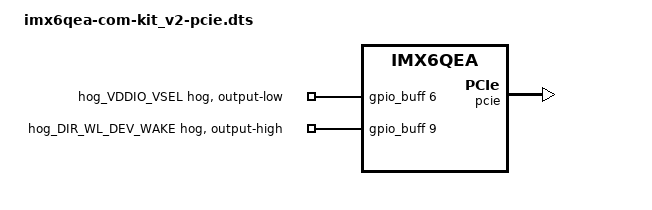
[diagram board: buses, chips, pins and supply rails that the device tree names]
/*
 * Copyright 2012 Freescale Semiconductor, Inc.
 * Copyright 2011 Linaro Ltd.
 *
 * The code contained herein is licensed under the GNU General Public
 * License. You may obtain a copy of the GNU General Public License
 * Version 2 or later at the following locations:
 *
 * http://www.opensource.org/licenses/gpl-license.html
 * http://www.gnu.org/copyleft/gpl.html
 */

/dts-v1/;
 
#include "imx6qea-com-kit_v2.dts"


&gpio_buff {
	hog_VDDIO_VSEL {
		gpio-hog;
		gpios = <6 0>;
		/delete-property/ output-high;
		output-low; /* LOW = 1.8V, HIGH = 3.3V */
	};
	hog_DIR_WL_DEV_WAKE {
		gpio-hog;
		gpios = <9 0>;
		/delete-property/ output-low;
		output-high;
	};
};

&usdhc2_pwrseq {
	status = "disabled";
};

&pcie {
	status = "okay";
};

&usdhc2 {
	status = "disabled";
};
